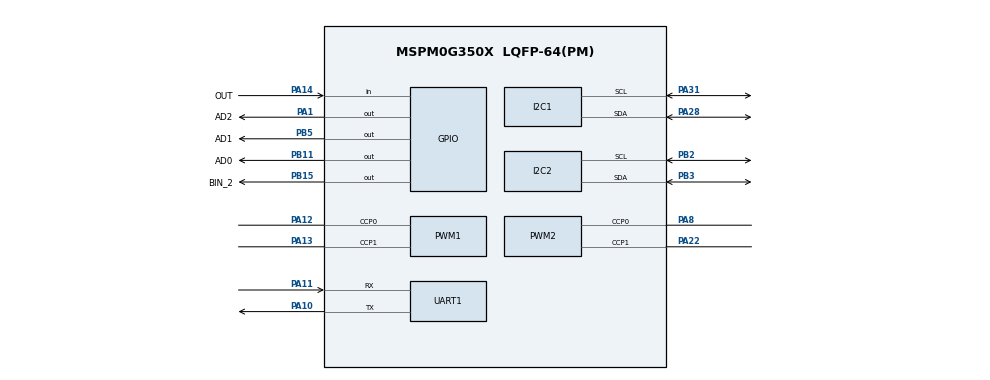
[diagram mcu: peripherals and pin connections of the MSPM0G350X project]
/**
 *
 * @cliArgs --device "MSPM0G350X" --part "Default" --package "LQFP-64(PM)" --product "mspm0_sdk@2.11.00.07"
 * @versions {"tool":"1.28.0+4696"}
 */

/**
 * Import the modules used in this configuration.
 */
const GPIO   = scripting.addModule("/ti/driverlib/GPIO", {}, false);
const GPIO1  = GPIO.addInstance();
const GPIO2  = GPIO.addInstance();
const GPIO3  = GPIO.addInstance();
const GPIO4  = GPIO.addInstance();
const GPIO5  = GPIO.addInstance();
const I2C    = scripting.addModule("/ti/driverlib/I2C", {}, false);
const I2C1   = I2C.addInstance();
const I2C2   = I2C.addInstance();
const PWM    = scripting.addModule("/ti/driverlib/PWM", {}, false);
const PWM1   = PWM.addInstance();
const PWM2   = PWM.addInstance();
const SYSCTL = scripting.addModule("/ti/driverlib/SYSCTL");
const TIMER  = scripting.addModule("/ti/driverlib/TIMER", {}, false);
const TIMER1 = TIMER.addInstance();
const UART   = scripting.addModule("/ti/driverlib/UART", {}, false);
const UART1  = UART.addInstance();
const UART2  = UART.addInstance();

/**
 * Write custom configuration values to the imported modules.
 */
GPIO1.$name                                 = "GPIO_MOTOR_A";
GPIO1.associatedPins.create(4);
GPIO1.associatedPins[0].$name               = "AIN_1";
GPIO1.associatedPins[0].assignedPortSegment = "Lower";
GPIO1.associatedPins[0].assignedPort        = "PORTB";
GPIO1.associatedPins[0].assignedPin         = "6";
GPIO1.associatedPins[1].$name               = "AIN_2";
GPIO1.associatedPins[1].assignedPort        = "PORTB";
GPIO1.associatedPins[1].assignedPin         = "7";
GPIO1.associatedPins[1].assignedPortSegment = "Lower";
GPIO1.associatedPins[2].$name               = "EA_1";
GPIO1.associatedPins[2].assignedPort        = "PORTB";
GPIO1.associatedPins[2].assignedPin         = "0";
GPIO1.associatedPins[2].direction           = "INPUT";
GPIO1.associatedPins[2].internalResistor    = "PULL_UP";
GPIO1.associatedPins[3].assignedPort        = "PORTB";
GPIO1.associatedPins[3].internalResistor    = "PULL_UP";
GPIO1.associatedPins[3].direction           = "INPUT";
GPIO1.associatedPins[3].$name               = "EB_1";
GPIO1.associatedPins[3].polarity            = "RISE_FALL";
GPIO1.associatedPins[3].interruptEn         = true;
GPIO1.associatedPins[3].assignedPin         = "16";

const Board = scripting.addModule("/ti/driverlib/Board", {}, false);

GPIO2.$name                              = "GPIO_MOTOR_B";
GPIO2.associatedPins.create(4);
GPIO2.associatedPins[0].$name            = "BIN_1";
GPIO2.associatedPins[0].assignedPort     = "PORTB";
GPIO2.associatedPins[0].assignedPin      = "8";
GPIO2.associatedPins[1].$name            = "BIN_2";
GPIO2.associatedPins[1].assignedPort     = "PORTB";
GPIO2.associatedPins[1].assignedPin      = "15";
GPIO2.associatedPins[1].pin.$assign      = "PB15";
GPIO2.associatedPins[2].$name            = "EA_2";
GPIO2.associatedPins[2].assignedPort     = "PORTB";
GPIO2.associatedPins[2].direction        = "INPUT";
GPIO2.associatedPins[2].internalResistor = "PULL_UP";
GPIO2.associatedPins[2].assignedPin      = "17";
GPIO2.associatedPins[3].assignedPort     = "PORTB";
GPIO2.associatedPins[3].internalResistor = "PULL_UP";
GPIO2.associatedPins[3].direction        = "INPUT";
GPIO2.associatedPins[3].$name            = "EB_2";
GPIO2.associatedPins[3].polarity         = "RISE_FALL";
GPIO2.associatedPins[3].interruptEn      = true;
GPIO2.associatedPins[3].assignedPin      = "12";

GPIO3.$name                              = "GPIO_MOTOR_C";
GPIO3.associatedPins.create(4);
GPIO3.associatedPins[0].$name            = "CIN_1";
GPIO3.associatedPins[0].assignedPort     = "PORTA";
GPIO3.associatedPins[0].assignedPin      = "26";
GPIO3.associatedPins[1].assignedPort     = "PORTB";
GPIO3.associatedPins[1].$name            = "CIN_2";
GPIO3.associatedPins[1].assignedPin      = "24";
GPIO3.associatedPins[2].$name            = "EA_3";
GPIO3.associatedPins[2].assignedPort     = "PORTB";
GPIO3.associatedPins[2].direction        = "INPUT";
GPIO3.associatedPins[2].internalResistor = "PULL_UP";
GPIO3.associatedPins[2].assignedPin      = "9";
GPIO3.associatedPins[3].internalResistor = "PULL_UP";
GPIO3.associatedPins[3].direction        = "INPUT";
GPIO3.associatedPins[3].$name            = "EB_3";
GPIO3.associatedPins[3].polarity         = "RISE_FALL";
GPIO3.associatedPins[3].interruptEn      = true;
GPIO3.associatedPins[3].assignedPort     = "PORTA";
GPIO3.associatedPins[3].assignedPin      = "27";

GPIO4.$name                              = "GPIO_MOTOR_D";
GPIO4.associatedPins.create(4);
GPIO4.associatedPins[0].$name            = "DIN_1";
GPIO4.associatedPins[0].assignedPort     = "PORTB";
GPIO4.associatedPins[0].assignedPin      = "18";
GPIO4.associatedPins[1].$name            = "DIN_2";
GPIO4.associatedPins[1].assignedPort     = "PORTA";
GPIO4.associatedPins[1].assignedPin      = "18";
GPIO4.associatedPins[2].$name            = "EA_4";
GPIO4.associatedPins[2].direction        = "INPUT";
GPIO4.associatedPins[2].internalResistor = "PULL_UP";
GPIO4.associatedPins[2].assignedPort     = "PORTA";
GPIO4.associatedPins[2].assignedPin      = "24";
GPIO4.associatedPins[3].internalResistor = "PULL_UP";
GPIO4.associatedPins[3].direction        = "INPUT";
GPIO4.associatedPins[3].$name            = "EB_4";
GPIO4.associatedPins[3].polarity         = "RISE_FALL";
GPIO4.associatedPins[3].interruptEn      = true;
GPIO4.associatedPins[3].assignedPort     = "PORTA";
GPIO4.associatedPins[3].assignedPin      = "17";

GPIO5.$name                              = "GPIO_GRAYSCALE";
GPIO5.associatedPins.create(4);
GPIO5.associatedPins[0].$name            = "AD0";
GPIO5.associatedPins[0].assignedPort     = "PORTB";
GPIO5.associatedPins[0].assignedPin      = "11";
GPIO5.associatedPins[0].pin.$assign      = "PB11";
GPIO5.associatedPins[1].$name            = "AD1";
GPIO5.associatedPins[1].assignedPort     = "PORTB";
GPIO5.associatedPins[1].assignedPin      = "5";
GPIO5.associatedPins[1].pin.$assign      = "PB5";
GPIO5.associatedPins[2].$name            = "AD2";
GPIO5.associatedPins[2].assignedPort     = "PORTA";
GPIO5.associatedPins[2].assignedPin      = "1";
GPIO5.associatedPins[2].pin.$assign      = "PA1";
GPIO5.associatedPins[3].$name            = "OUT";
GPIO5.associatedPins[3].direction        = "INPUT";
GPIO5.associatedPins[3].internalResistor = "PULL_UP";
GPIO5.associatedPins[3].assignedPort     = "PORTA";
GPIO5.associatedPins[3].assignedPin      = "14";
GPIO5.associatedPins[3].pin.$assign      = "PA14";

I2C1.$name                             = "I2C_MPU6050";
I2C1.basicEnableController             = true;
I2C1.basicControllerStandardBusSpeed   = "Fast";
I2C1.peripheral.sdaPin.$assign         = "PA28";
I2C1.peripheral.sclPin.$assign         = "PA31";
I2C1.sdaPinConfig.hideOutputInversion  = scripting.forceWrite(false);
I2C1.sdaPinConfig.onlyInternalResistor = scripting.forceWrite(false);
I2C1.sdaPinConfig.passedPeripheralType = scripting.forceWrite("Digital");
I2C1.sdaPinConfig.$name                = "ti_driverlib_gpio_GPIOPinGeneric4";
I2C1.sclPinConfig.hideOutputInversion  = scripting.forceWrite(false);
I2C1.sclPinConfig.onlyInternalResistor = scripting.forceWrite(false);
I2C1.sclPinConfig.passedPeripheralType = scripting.forceWrite("Digital");
I2C1.sclPinConfig.$name                = "ti_driverlib_gpio_GPIOPinGeneric5";

I2C2.$name                             = "I2C_OLED";
I2C2.basicEnableController             = true;
I2C2.basicControllerStandardBusSpeed   = "Fast";
I2C2.peripheral.sdaPin.$assign         = "PB3";
I2C2.peripheral.sclPin.$assign         = "PB2";
I2C2.sdaPinConfig.hideOutputInversion  = scripting.forceWrite(false);
I2C2.sdaPinConfig.onlyInternalResistor = scripting.forceWrite(false);
I2C2.sdaPinConfig.passedPeripheralType = scripting.forceWrite("Digital");
I2C2.sdaPinConfig.$name                = "ti_driverlib_gpio_GPIOPinGeneric10";
I2C2.sclPinConfig.hideOutputInversion  = scripting.forceWrite(false);
I2C2.sclPinConfig.onlyInternalResistor = scripting.forceWrite(false);
I2C2.sclPinConfig.passedPeripheralType = scripting.forceWrite("Digital");
I2C2.sclPinConfig.$name                = "ti_driverlib_gpio_GPIOPinGeneric11";

PWM1.clockDivider                       = 8;
PWM1.clockPrescale                      = 40;
PWM1.timerCount                         = 100;
PWM1.$name                              = "PWM_MOTOR_AB";
PWM1.peripheral.$assign                 = "TIMG0";
PWM1.peripheral.ccp0Pin.$assign         = "PA12";
PWM1.peripheral.ccp1Pin.$assign         = "PA13";
PWM1.PWM_CHANNEL_0.$name                = "ti_driverlib_pwm_PWMTimerCC0";
PWM1.PWM_CHANNEL_1.$name                = "ti_driverlib_pwm_PWMTimerCC1";
PWM1.ccp0PinConfig.direction            = scripting.forceWrite("OUTPUT");
PWM1.ccp0PinConfig.hideOutputInversion  = scripting.forceWrite(false);
PWM1.ccp0PinConfig.onlyInternalResistor = scripting.forceWrite(false);
PWM1.ccp0PinConfig.passedPeripheralType = scripting.forceWrite("Digital");
PWM1.ccp0PinConfig.$name                = "ti_driverlib_gpio_GPIOPinGeneric0";
PWM1.ccp1PinConfig.direction            = scripting.forceWrite("OUTPUT");
PWM1.ccp1PinConfig.hideOutputInversion  = scripting.forceWrite(false);
PWM1.ccp1PinConfig.onlyInternalResistor = scripting.forceWrite(false);
PWM1.ccp1PinConfig.passedPeripheralType = scripting.forceWrite("Digital");
PWM1.ccp1PinConfig.$name                = "ti_driverlib_gpio_GPIOPinGeneric1";

PWM2.clockDivider                       = 8;
PWM2.clockPrescale                      = 40;
PWM2.timerCount                         = 100;
PWM2.$name                              = "PWM_MOTOR_CD";
PWM2.peripheral.$assign                 = "TIMA0";
PWM2.peripheral.ccp0Pin.$assign         = "PA8";
PWM2.peripheral.ccp1Pin.$assign         = "PA22";
PWM2.PWM_CHANNEL_0.$name                = "ti_driverlib_pwm_PWMTimerCC2";
PWM2.PWM_CHANNEL_1.$name                = "ti_driverlib_pwm_PWMTimerCC3";
PWM2.ccp0PinConfig.direction            = scripting.forceWrite("OUTPUT");
PWM2.ccp0PinConfig.hideOutputInversion  = scripting.forceWrite(false);
PWM2.ccp0PinConfig.onlyInternalResistor = scripting.forceWrite(false);
PWM2.ccp0PinConfig.passedPeripheralType = scripting.forceWrite("Digital");
PWM2.ccp0PinConfig.$name                = "ti_driverlib_gpio_GPIOPinGeneric8";
PWM2.ccp1PinConfig.direction            = scripting.forceWrite("OUTPUT");
PWM2.ccp1PinConfig.hideOutputInversion  = scripting.forceWrite(false);
PWM2.ccp1PinConfig.onlyInternalResistor = scripting.forceWrite(false);
PWM2.ccp1PinConfig.passedPeripheralType = scripting.forceWrite("Digital");
PWM2.ccp1PinConfig.$name                = "ti_driverlib_gpio_GPIOPinGeneric9";

SYSCTL.forceDefaultClkConfig = true;

TIMER1.$name       = "TIMER_PID";
TIMER1.interrupts  = ["ZERO"];
TIMER1.timerPeriod = "10ms";
TIMER1.timerClkDiv = 5;
TIMER1.timerMode   = "PERIODIC";

UART1.$name                    = "UART_0";
UART1.enabledInterrupts        = ["RX"];
UART1.targetBaudRate           = 115200;
UART1.peripheral.rxPin.$assign = "PA11";
UART1.peripheral.txPin.$assign = "PA10";
UART1.txPinConfig.$name        = "ti_driverlib_gpio_GPIOPinGeneric2";
UART1.rxPinConfig.$name        = "ti_driverlib_gpio_GPIOPinGeneric3";

UART2.$name             = "UART_1";
UART2.txPinConfig.$name = "ti_driverlib_gpio_GPIOPinGeneric6";
UART2.rxPinConfig.$name = "ti_driverlib_gpio_GPIOPinGeneric7";

/**
 * Pinmux solution for unlocked pins/peripherals. This ensures that minor changes to the automatic solver in a future
 * version of the tool will not impact the pinmux you originally saw.  These lines can be completely deleted in order to
 * re-solve from scratch.
 */
GPIO1.associatedPins[0].pin.$suggestSolution = "PB6";
GPIO1.associatedPins[1].pin.$suggestSolution = "PB7";
GPIO1.associatedPins[2].pin.$suggestSolution = "PB0";
GPIO1.associatedPins[3].pin.$suggestSolution = "PB16";
Board.peripheral.$suggestSolution            = "DEBUGSS";
Board.peripheral.swclkPin.$suggestSolution   = "PA20";
Board.peripheral.swdioPin.$suggestSolution   = "PA19";
GPIO2.associatedPins[0].pin.$suggestSolution = "PB8";
GPIO2.associatedPins[2].pin.$suggestSolution = "PB17";
GPIO2.associatedPins[3].pin.$suggestSolution = "PB12";
GPIO3.associatedPins[0].pin.$suggestSolution = "PA26";
GPIO3.associatedPins[1].pin.$suggestSolution = "PB24";
GPIO3.associatedPins[2].pin.$suggestSolution = "PB9";
GPIO3.associatedPins[3].pin.$suggestSolution = "PA27";
GPIO4.associatedPins[0].pin.$suggestSolution = "PB18";
GPIO4.associatedPins[1].pin.$suggestSolution = "PA18";
GPIO4.associatedPins[2].pin.$suggestSolution = "PA24";
GPIO4.associatedPins[3].pin.$suggestSolution = "PA17";
I2C1.peripheral.$suggestSolution             = "I2C0";
I2C2.peripheral.$suggestSolution             = "I2C1";
SYSCTL.peripheral.$suggestSolution           = "SYSCTL";
TIMER1.peripheral.$suggestSolution           = "TIMA1";
UART1.peripheral.$suggestSolution            = "UART0";
UART2.peripheral.$suggestSolution            = "UART1";
UART2.peripheral.rxPin.$suggestSolution      = "PA9";
UART2.peripheral.txPin.$suggestSolution      = "PB4";
